# HDQ1-Wire register map
Vendor: Texas Instruments
Peripheral module from a debugger description file (folder omap36xx).
Registers are 32-bit, read-only, reset 0x0 unless marked. A register's access mark holds for its fields unless they carry their own. Offsets are as the file gives them; lines under a group give offsets from that group; [hi:lo] are bit positions; {n}, {i} and the like mark numbered series; 'fields as' and 'values as' point back to an identical list; <NAME> marks a mode.

## HDQ/1-Wire
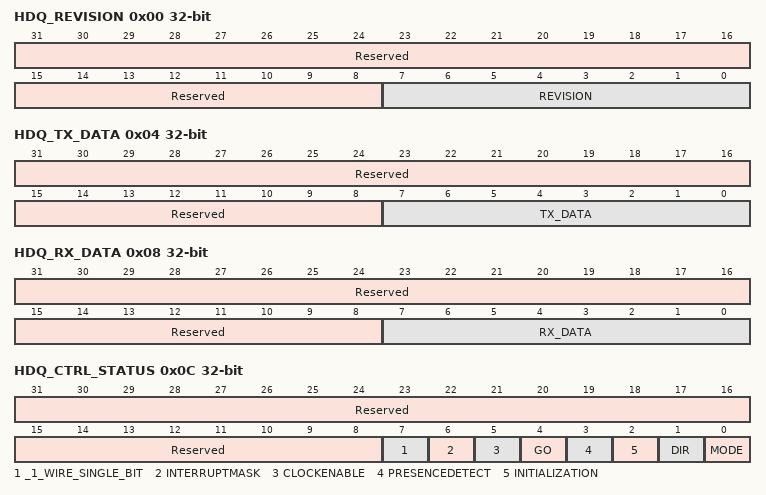
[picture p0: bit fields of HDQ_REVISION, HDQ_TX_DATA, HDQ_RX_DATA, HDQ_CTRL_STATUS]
0x00 HDQ_REVISION (reset mask 0xFFFFFF00) — This register contains the IP revision code.
  [31:8] Reserved — Reads return 0s.
  [7:0] REVISION — IP revisionThe 4 LSBs indicate a minor revision. The 4 MSBs indicate a major revision. Ex: 0x21: Revision 2.1
0x04 HDQ_TX_DATA access per field — This register contains the data to be transmitted.
  [31:8] Reserved ro — Reads return 0s.
  [7:0] TX_DATA rw — Transmit data (used in both HDQ and 1-Wire modes)
0x08 HDQ_RX_DATA — This register contains the data to be received.
  [31:8] Reserved — Reads return 0s.
  [7:0] RX_DATA — Receive data (used in both HDQ and 1-Wire modes)
0x0C HDQ_CTRL_STATUS access per field — This register provides status information about the module.
  [31:8] Reserved ro — Reads return 0s.
  [7] _1_WIRE_SINGLE_BIT rw — Single-bit mode for 1-Wire
    0=1_WIRE_SINGLE_BIT_0 (Disabled); 1=1_WIRE_SINGLE_BIT_1 (Enabled)
  [6] INTERRUPTMASK rw — Interrupt masking bit
    0=Disable interrupts; 1=Enable interrupts
  [5] CLOCKENABLE rw — Power down mode bit
    0=Disable clocks; 1=Enable clocks
  [4] GO rw — Go bitWrite 1 to send the appropriate commands. Bit returns to 0 after the command is complete.
  [3] PRESENCEDETECT ro — Presence detect received, 1-Wire mode only
    0=Not detected; 1=Detected
  [2] INITIALIZATION rw — Write 1 to send initialization pulse.Bit returns to 0 after pulse is sent.
  [1] DIR rw — DIR bit, determines if next command is read or write
    0=Write; 1=Read
  [0] MODE rw — Mode selection bit
    0=HDQ mode; 1=1-Wire mode
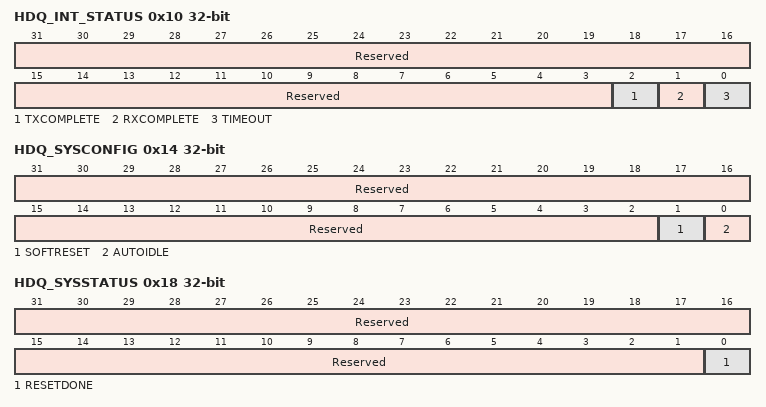
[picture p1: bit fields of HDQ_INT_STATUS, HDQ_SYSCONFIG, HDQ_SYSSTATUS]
0x10 HDQ_INT_STATUS — This register controls interrupt status.
  [31:3] Reserved — Reads return 0s.
  [2] TXCOMPLETE — TX-complete interrupt flagSet to 1 if cause of interrupt. Set to 0 when register read.
  [1] RXCOMPLETE — Read-complete interrupt flagSet to 1 if cause of interrupt. Set to 0 when register read.
  [0] TIMEOUT — Presence detect/timeout interrupt flagIn 1-Wire mode, set to 1 if slave's presence detected. In HDQ mode, set to 1 if timeout on read occurs. Set to 0 when register read.
0x14 HDQ_SYSCONFIG access per field — This register controls various bits.
  [31:2] Reserved ro — Reads return 0s.
  [1] SOFTRESET rw — Start soft reset sequence.
    0=Disabled; 1=Enabled
  [0] AUTOIDLE rw — Interconnect idle
    0=Module clock is free-running; 1=Module is in power saving mode: Clock is running only when module is accessed or inside logic is in function to process events
0x18 HDQ_SYSSTATUS (reset mask 0xFFFFFFFE) — This register monitors the reset sequence.
  [31:1] Reserved — Reads return 0s.
  [0] RESETDONE — Reset monitoring
    0=The module is currently performing its reset. When the module is in power-down mode, set to 0 to indicate this fact.; 1=The module has finished its reset
